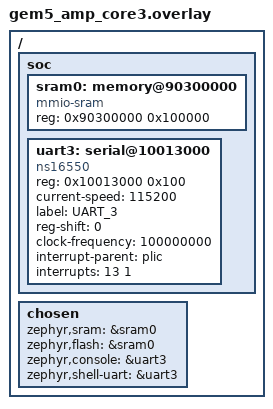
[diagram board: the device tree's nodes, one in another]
/ {
    soc {
        sram0: memory@90300000 {
            compatible = "mmio-sram";
            reg = <0x90300000 0x100000>;
        };
        
        uart3: serial@10013000 {
            compatible = "ns16550";
            reg = <0x10013000 0x100>;
            status = "okay";
            current-speed = <115200>;
            label = "UART_3";
            reg-shift = <0>;
            clock-frequency = <100000000>;
            interrupt-parent = <&plic>;
            interrupts = <13 1>;
        };
    };

    chosen {
        zephyr,sram = &sram0;
        zephyr,flash = &sram0;
        zephyr,console = &uart3;
        zephyr,shell-uart = &uart3;
    };
};

